# R40 register map
Vendor: Allwinner; Series: R40; File version: 0.1
CPU: CA7 0, little endian, MPU, FPU, double-precision FPU, 0 interrupt priority bits
Registers are 32-bit, read-write, reset 0x0 unless marked. A register's access mark holds for its fields unless they carry their own. Offsets are from the block's base; [hi:lo] are bit positions.

## TWI0
Base 0x01C2AC00
Same registers: TWI1 0x01C2B000, TWI2 0x01C2B400, TWI3 0x01C2B800, TWI4 0x01C2C000
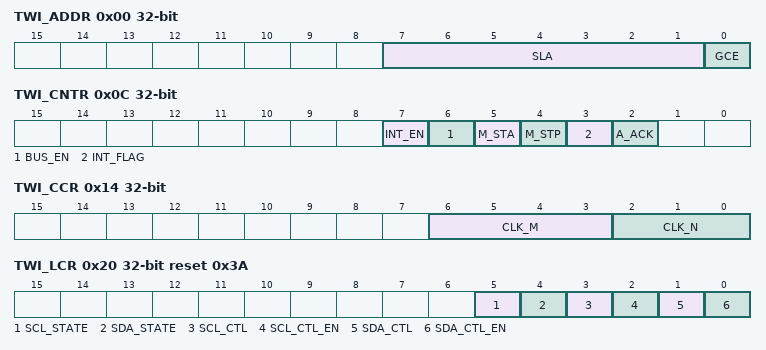
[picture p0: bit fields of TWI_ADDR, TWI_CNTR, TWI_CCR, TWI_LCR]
0x00 TWI_ADDR — TWI Slave Address
  [7:1] SLA — Slave address 7-bit addressing SLA6, SLA5, SLA4, SLA3, SLA2, SLA1, SLA0 10-bit addressing 1, 1, 1, 1, 0, SLAX[9:8]
  [0] GCE — General call address enable 0: Disable 1: Enable
    0=Disable; 1=Enable
0x04 TWI_XADDR — TWI Extended Slave Address
  [7:0] SLAX — Extend Slave Address SLAX[7:0]
0x08 TWI_DATA — TWI Data Byte
  [7:0] TWI_DATA — Data byte for transmitting or received
0x0C TWI_CNTR — TWI Control Register
  [7] INT_EN — Interrupt Enable 0: The interrupt line always low 1: The interrupt line will go high when is set.
    0=interrupt_line_always_low (The interrupt line always low); 1=interrupt_line_will_go (The interrupt line will go high when is set.)
  [6] BUS_EN — TWI Bus Enable 0: The TWI bus inputs ISDA/ISCL are ignored and the TWI Controller will not respond to any address on the bus 1: The TWI will respond to calls to its slave address and the general call address if the bit in the is set. Note: In master operation mode, this bit should be set to `1`.
    0=TWI_bus (The TWI bus inputs ISDA/ISCL are ignored and the TWI Controller will not respond to any address on the bus); 1=TWI_will_respond (The TWI will respond to calls to its slave address and the general call address if the bit in the is set. Note: In master operation mode, this bit should be set to `1`.)
  [5] M_STA — Master Mode Start When is set to `1`, TWI Controller enters master mode and will transmit a START condition on the bus when the bus is free. If the bit is set to `1` when the TWI Controller is already in master mode and one or more bytes have been transmitted, then a repeated START condition will be sent. If the bit is set to `1` when the TWI is being accessed in slave mode, the TWI will complete the data transfer in slave mode then enter master mode when the bus has been released. The bit is cleared automatically after a START condition has been sent: writing a `0` to this bit has no effect.
  [4] M_STP write-1-clears — Master Mode Stop If is set to `1` in master mode, a STOP condition is transmitted on the TWI bus. If the bit is set to `1` in slave mode, the TWI will behave as if a STOP condition has been received, but no STOP condition will be transmitted on the TWI bus. If both M_STA and bits are set, the TWI will first transmit the STOP condition (if in master mode) then transmit the START condition. The bit is cleared automatically, writing a `0` to this bit has no effect.
  [3] INT_FLAG write-1-clears — Interrupt Flag is automatically set to `1` when any of 28 (out of the possible 29) states is entered (see ` ` below). The only state that does not set is state F8h. If the bit is set, the interrupt line goes high when IFLG is set to `1`. If the TWI is operating in slave mode, data transfer is suspended when is set and the low period of the TWI bus clock line (SCL) is stretched until `1` is written to . The TWI clock line is then released and the interrupt line goes low.
  [2] A_ACK — Assert Acknowledge When A_ACK is set to `1`, an Acknowledge (low level on SDA) will be sent during the acknowledge clock pulse on the TWI bus if: (1). Either the whole of a matching 7-bit slave address or the first or the second byte of a matching 10-bit slave address has been received. (2). The general call address has been received and the bit in the register is set to `1`. (3). A data byte has been received in master or slave mode. When A_ACK is `0`, a Not Acknowledge (high level on SDA) will be sent when a data byte is received in master or slave mode. If A_ACK is cleared to `0` in slave transmitter mode, the byte in the register is assumed to be the `last byte`. After this byte has been transmitted, the TWI will enter state C8h then return to the idle state (status code F8h) when is cleared. The TWI will not respond as a slave unless A_ACK is set.
0x10 TWI_STAT reset 0xF8 — TWI Status Register
  [7:0] STA ro — Status Information Byte Code Status 0x00: Bus error 0x08: START condition transmitted 0x10: Repeated START condition transmitted 0x18: Address + Write bit transmitted, ACK received 0x20: Address + Write bit transmitted, ACK not received 0x28: Data byte transmitted in master mode, ACK received 0x30: Data byte transmitted in master mode, ACK not received 0x38: Arbitration lost in address or data byte 0x40: Address + Read bit transmitted, ACK received 0x48: Address + Read bit transmitted, ACK not received 0x50: Data byte received in master mode, ACK transmitted 0x58: Data byte received in master mode, not ACK transmitted 0x60: Slave address + Write bit received, ACK transmitted 0x68: Arbitration lost in address as master, slave address + Write bit received, ACK transmitted 0x70: General Call address received, ACK transmitted 0x78: Arbitration lost in address as master, General Call address received, ACK transmitted 0x80: Data byte received after slave address received, ACK transmitted 0x88: Data byte received after slave address received, not ACK transmitted 0x90: Data byte received after General Call received, ACK transmitted 0x98: Data byte received after General Call received, not ACK transmitted 0xA0: STOP or repeated START condition received in slave mode 0xA8: Slave address + Read bit received, ACK transmitted 0xB0: Arbitration lost in address as master, slave address + Read bit received, ACK transmitted 0xB8: Data byte transmitted in slave mode, ACK received 0xC0: Data byte transmitted in slave mode, ACK not received 0xC8: Last byte transmitted in slave mode, ACK received 0xD0: Second Address byte + Write bit transmitted, ACK received 0xD8: Second Address byte + Write bit transmitted, ACK not received 0xF8: No relevant status information, INT_FLAG=0 Others: Reserved
0x14 TWI_CCR — TWI Clock Control Register
  [6:3] CLK_M
  [2:0] CLK_N — The TWI bus is sampled by the TWI at the frequency defined by F0: Fsamp = F 0 = Fin / 2^CLK_N The TWI OSCL output frequency, in master mode, is F1 / 10: F1 = F0 / (CLK_M + 1) Foscl = F1 / 10 = Fin / (2^CLK_N * (CLK_M + 1)*10) For Example Fin = 48Mhz (APB clock input) For 400kHz full speed 2Wire, CLK_N = 2, CLK_M=2 F0 = 48M/2^2=12Mhz, F1= F0/(10*(2+1)) = 0.4Mhz For 100Khz standard speed 2Wire, CLK_N=2, CLK_M=11 F0=48M/2^2=12Mhz, F1=F0/(10*(11+1)) = 0.1Mhz
0x18 TWI_SRST — TWI Software Reset
  [0] SOFT_RST — Soft Reset Write `1` to this bit to reset the TWI and clear to `0` when completing Soft Reset operation.
0x1C TWI_EFR — TWI Enhance Feature Register
  [1:0] DBN — Data Byte number follow Read Command Control 00: No Data Byte to be written after read command 01: Only 1 byte data to be written after read command 10: 2 bytes data can be written after read command 11: 3 bytes data can be written after read command
    0=No Data Byte to be written after read command; 1=Only 1 byte data to be written after read command; 2=2 bytes data can be written after read command; 3=3 bytes data can be written after read command
0x20 TWI_LCR reset 0x3A — TWI Line Control Register
  [5] SCL_STATE ro — Current state of TWI_SCL 0: Low 1: High
    0=Low; 1=High
  [4] SDA_STATE ro — Current state of TWI_SDA 0: Low 1: High
    0=Low; 1=High
  [3] SCL_CTL — TWI_SCL line state control bit When line control mode is enabled (bit[2] set), the value of this bit decides the output level of TWI_SCL. 0: Output low level 1: Output high level
    0=Output_low_level; 1=Output_high_level
  [2] SCL_CTL_EN — TWI_SCL line state control enable When this bit is set, the state of TWI_SCL is controlled by the value of bit[3]. 0: Disable TWI_SCL line control mode 1: Enable TWI_SCL line control mode
    0=Disable TWI_SCL line control mode; 1=Enable TWI_SCL line control mode
  [1] SDA_CTL — TWI_SDA line state control bit When line control mode is enabled (bit[0] set), the value of this bit decides the output level of TWI_SDA. 0: Output low level 1: Output high level
    0=Output_low_level; 1=Output_high_level
  [0] SDA_CTL_EN — TWI_SDA line state control enable When this bit is set, the state of TWI_SDA is controlled by the value of bit[1]. 0: Disable TWI_SDA line control mode 1: Enable TWI_SDA line control mode
    0=Disable TWI_SDA line control mode; 1=Enable TWI_SDA line control mode
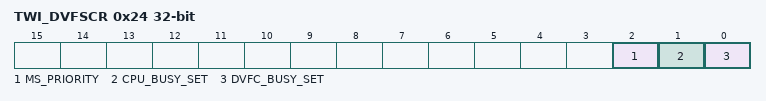
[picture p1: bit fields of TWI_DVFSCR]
0x24 TWI_DVFSCR
  [2] MS_PRIORITY — CPU and DVFS BUSY set priority select 0: CPU has higher priority 1: DVFS has higher priority
    0=CPU (CPU has higher priority); 1=DVFS (DVFS has higher priority)
  [1] CPU_BUSY_SET
  [0] DVFC_BUSY_SET — DVFS Busy set
